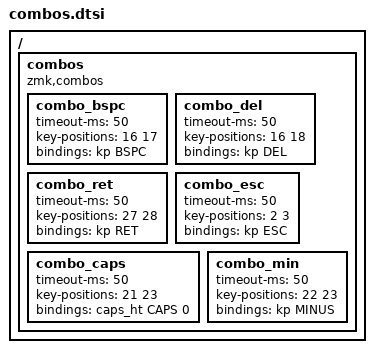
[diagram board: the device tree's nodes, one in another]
/ {
    // 0  1  2  3  4      5  6  7  8  9
    // 10 11 12 13 14     15 16 17 18 19
    // 20 21 22 23 24     25 26 27 28 29
    //       30 31 32     33 34 35

    combos {
        compatible = "zmk,combos";

        // BSPC = N E
        combo_bspc {
            timeout-ms = <50>;
            key-positions = <16 17>;
            bindings = <&kp BSPC>;
        };

        // DEL = N I
        combo_del {
            timeout-ms = <50>;
            key-positions = <16 18>;
            bindings = <&kp DEL>;
        };

        // ENTER = , .
        combo_ret {
            timeout-ms = <50>;
            key-positions = <27 28>;
            bindings = <&kp RET>;
        };

        // ESC = F P
        combo_esc {
            timeout-ms = <50>;
            key-positions = <2 3>;
            bindings = <&kp ESC>;
        };

        // CAPS = X V
        combo_caps {
            timeout-ms = <50>;
            key-positions = <21 23>;
            bindings = <&caps_ht CAPS 0>;
        };

        // MINUS = C V
        combo_min {
            timeout-ms = <50>;
            key-positions = <22 23>;
            bindings = <&kp MINUS>;
        };
    };
};
